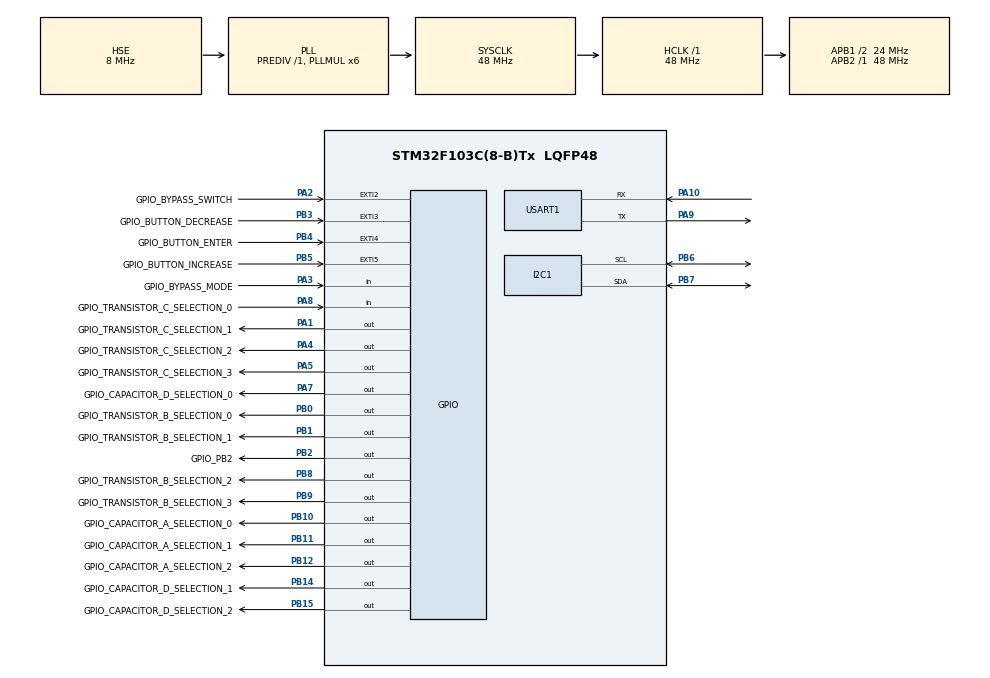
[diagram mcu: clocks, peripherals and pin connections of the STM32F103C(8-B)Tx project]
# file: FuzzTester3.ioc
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I2C1.I2C_Mode=I2C_Standard
Mcu.Family=STM32F1
Mcu.Name=STM32F103C(8-B)Tx
Mcu.Package=LQFP48
NVIC.EXTI2_IRQn=true\:0\:0\:false\:false\:true\:true\:true
NVIC.EXTI3_IRQn=true\:0\:0\:false\:false\:true\:true\:true
NVIC.EXTI4_IRQn=true\:0\:0\:false\:false\:true\:true\:true
NVIC.EXTI9_5_IRQn=true\:0\:0\:false\:false\:true\:true\:true
NVIC.PriorityGroup=NVIC_PRIORITYGROUP_4
PA1.GPIO_Label=GPIO_TRANSISTOR_C_SELECTION_1
PA1.Signal=GPIO_Output
PA10.Mode=Asynchronous
PA10.Signal=USART1_RX
PA13.Mode=Serial_Wire
PA13.Signal=SYS_JTMS-SWDIO
PA14.Mode=Serial_Wire
PA14.Signal=SYS_JTCK-SWCLK
PA2.GPIO_Label=GPIO_BYPASS_SWITCH
PA2.GPIO_PuPd=GPIO_PULLDOWN
PA2.Signal=GPXTI2
PA3.GPIO_Label=GPIO_BYPASS_MODE
PA3.Signal=GPIO_Input
PA4.GPIO_Label=GPIO_TRANSISTOR_C_SELECTION_2
PA4.Signal=GPIO_Output
PA5.GPIO_Label=GPIO_TRANSISTOR_C_SELECTION_3
PA5.Signal=GPIO_Output
PA7.GPIO_Label=GPIO_CAPACITOR_D_SELECTION_0
PA7.Signal=GPIO_Output
PA8.GPIO_Label=GPIO_TRANSISTOR_C_SELECTION_0
PA8.Signal=GPIO_Input
PA9.Mode=Asynchronous
PA9.Signal=USART1_TX
PB0.GPIO_Label=GPIO_TRANSISTOR_B_SELECTION_0
PB0.Signal=GPIO_Output
PB1.GPIO_Label=GPIO_TRANSISTOR_B_SELECTION_1
PB1.Signal=GPIO_Output
PB10.GPIO_Label=GPIO_CAPACITOR_A_SELECTION_0
PB10.Signal=GPIO_Output
PB11.GPIO_Label=GPIO_CAPACITOR_A_SELECTION_1
PB11.Signal=GPIO_Output
PB12.GPIO_Label=GPIO_CAPACITOR_A_SELECTION_2
PB12.Signal=GPIO_Output
PB14.GPIO_Label=GPIO_CAPACITOR_D_SELECTION_1
PB14.Signal=GPIO_Output
PB15.GPIO_Label=GPIO_CAPACITOR_D_SELECTION_2
PB15.Signal=GPIO_Output
PB2.GPIO_Label=GPIO_PB2
PB2.GPIO_PuPd=GPIO_NOPULL
PB2.Signal=GPIO_Output
PB3.GPIO_Label=GPIO_BUTTON_DECREASE
PB3.GPIO_PuPd=GPIO_PULLDOWN
PB3.Signal=GPXTI3
PB4.GPIO_Label=GPIO_BUTTON_ENTER
PB4.GPIO_PuPd=GPIO_PULLDOWN
PB4.Signal=GPXTI4
PB5.GPIO_Label=GPIO_BUTTON_INCREASE
PB5.GPIO_PuPd=GPIO_PULLDOWN
PB5.Signal=GPXTI5
PB6.Mode=I2C
PB6.Signal=I2C1_SCL
PB7.Mode=I2C
PB7.Signal=I2C1_SDA
PB8.GPIO_Label=GPIO_TRANSISTOR_B_SELECTION_2
PB8.Signal=GPIO_Output
PB9.GPIO_Label=GPIO_TRANSISTOR_B_SELECTION_3
PB9.Signal=GPIO_Output
PD0-OSC_IN.Mode=HSE-External-Oscillator
PD0-OSC_IN.Signal=RCC_OSC_IN
PD1-OSC_OUT.Mode=HSE-External-Oscillator
PD1-OSC_OUT.Signal=RCC_OSC_OUT
ProjectManager.HeapSize=0x200
ProjectManager.StackSize=0x400
ProjectManager.TargetToolchain=STM32CubeIDE
RCC.ADCPresc=RCC_ADCPCLK2_DIV6
RCC.AHBFreq_Value=48000000
RCC.APB1CLKDivider=RCC_HCLK_DIV2
RCC.APB1Freq_Value=24000000
RCC.APB1TimFreq_Value=48000000
RCC.APB2Freq_Value=48000000
RCC.APB2TimFreq_Value=48000000
RCC.HCLKFreq_Value=48000000
RCC.PLLMUL=RCC_PLL_MUL6
RCC.PLLSourceVirtual=RCC_PLLSOURCE_HSE
RCC.SYSCLKFreq_VALUE=48000000
RCC.SYSCLKSource=RCC_SYSCLKSOURCE_PLLCLK
RCC.USBFreq_Value=48000000
USART1.VirtualMode=VM_ASYNC
board=custom

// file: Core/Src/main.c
/* USER CODE BEGIN Header */
/**
  ******************************************************************************
  * @file           : main.c
  * @brief          : Main program body
  ******************************************************************************
  * @attention
  *
  * <h2><center>&copy; Copyright (c) 2020 STMicroelectronics.
  * All rights reserved.</center></h2>
  *
  * This software component is licensed by ST under BSD 3-Clause license,
  * the "License"; You may not use this file except in compliance with the
  * License. You may obtain a copy of the License at:
  *                        opensource.org/licenses/BSD-3-Clause
  *
  ******************************************************************************
  */
/* USER CODE END Header */

#include "main.h"

I2C_HandleTypeDef hi2c1;

UART_HandleTypeDef huart1;

void SystemClock_Config(void);
static void MX_GPIO_Init(void);
static void MX_I2C1_Init(void);
static void MX_USART1_UART_Init(void);
/* USER CODE BEGIN PFP */

void MyInit();
int  MyMain();

/* USER CODE END PFP */

int main(void)
{

  /* MCU Configuration--------------------------------------------------------*/

  /* Reset of all peripherals, Initializes the Flash interface and the Systick. */
  HAL_Init();

  /* Configure the system clock */
  SystemClock_Config();

  /* Initialize all configured peripherals */
  MX_GPIO_Init();
  MX_I2C1_Init();
  MX_USART1_UART_Init();

  /* Infinite loop */
  /* USER CODE BEGIN WHILE */
  MyInit();
  while (1)
  {
     MyMain();

    /* USER CODE END WHILE */

  }
}

void SystemClock_Config(void)
{
  RCC_OscInitTypeDef RCC_OscInitStruct = {0};
  RCC_ClkInitTypeDef RCC_ClkInitStruct = {0};

  /** Initializes the CPU, AHB and APB busses clocks
  */
  RCC_OscInitStruct.OscillatorType = RCC_OSCILLATORTYPE_HSE;
  RCC_OscInitStruct.HSEState = RCC_HSE_ON;
  RCC_OscInitStruct.HSEPredivValue = RCC_HSE_PREDIV_DIV1;
  RCC_OscInitStruct.HSIState = RCC_HSI_ON;
  RCC_OscInitStruct.PLL.PLLState = RCC_PLL_ON;
  RCC_OscInitStruct.PLL.PLLSource = RCC_PLLSOURCE_HSE;
  RCC_OscInitStruct.PLL.PLLMUL = RCC_PLL_MUL6;
  if (HAL_RCC_OscConfig(&RCC_OscInitStruct) != HAL_OK)
  {
    Error_Handler();
  }
  /** Initializes the CPU, AHB and APB busses clocks
  */
  RCC_ClkInitStruct.ClockType = RCC_CLOCKTYPE_HCLK|RCC_CLOCKTYPE_SYSCLK
                              |RCC_CLOCKTYPE_PCLK1|RCC_CLOCKTYPE_PCLK2;
  RCC_ClkInitStruct.SYSCLKSource = RCC_SYSCLKSOURCE_PLLCLK;
  RCC_ClkInitStruct.AHBCLKDivider = RCC_SYSCLK_DIV1;
  RCC_ClkInitStruct.APB1CLKDivider = RCC_HCLK_DIV2;
  RCC_ClkInitStruct.APB2CLKDivider = RCC_HCLK_DIV1;

  if (HAL_RCC_ClockConfig(&RCC_ClkInitStruct, FLASH_LATENCY_1) != HAL_OK)
  {
    Error_Handler();
  }
}

static void MX_I2C1_Init(void)
{

  hi2c1.Instance = I2C1;
  hi2c1.Init.ClockSpeed = 100000;
  hi2c1.Init.DutyCycle = I2C_DUTYCYCLE_2;
  hi2c1.Init.OwnAddress1 = 0;
  hi2c1.Init.AddressingMode = I2C_ADDRESSINGMODE_7BIT;
  hi2c1.Init.DualAddressMode = I2C_DUALADDRESS_DISABLE;
  hi2c1.Init.OwnAddress2 = 0;
  hi2c1.Init.GeneralCallMode = I2C_GENERALCALL_DISABLE;
  hi2c1.Init.NoStretchMode = I2C_NOSTRETCH_DISABLE;
  if (HAL_I2C_Init(&hi2c1) != HAL_OK)
  {
    Error_Handler();
  }

}

static void MX_USART1_UART_Init(void)
{

  huart1.Instance = USART1;
  huart1.Init.BaudRate = 115200;
  huart1.Init.WordLength = UART_WORDLENGTH_8B;
  huart1.Init.StopBits = UART_STOPBITS_1;
  huart1.Init.Parity = UART_PARITY_NONE;
  huart1.Init.Mode = UART_MODE_TX_RX;
  huart1.Init.HwFlowCtl = UART_HWCONTROL_NONE;
  huart1.Init.OverSampling = UART_OVERSAMPLING_16;
  if (HAL_UART_Init(&huart1) != HAL_OK)
  {
    Error_Handler();
  }

}

static void MX_GPIO_Init(void)
{
  GPIO_InitTypeDef GPIO_InitStruct = {0};

  /* GPIO Ports Clock Enable */
  __HAL_RCC_GPIOD_CLK_ENABLE();
  __HAL_RCC_GPIOA_CLK_ENABLE();
  __HAL_RCC_GPIOB_CLK_ENABLE();

  /*Configure GPIO pin Output Level */
  HAL_GPIO_WritePin(GPIOA, GPIO_TRANSISTOR_C_SELECTION_1_Pin|GPIO_TRANSISTOR_C_SELECTION_2_Pin|GPIO_TRANSISTOR_C_SELECTION_3_Pin|GPIO_CAPACITOR_D_SELECTION_0_Pin, GPIO_PIN_RESET);

  /*Configure GPIO pin Output Level */
  HAL_GPIO_WritePin(GPIOB, GPIO_TRANSISTOR_B_SELECTION_0_Pin|GPIO_TRANSISTOR_B_SELECTION_1_Pin|GPIO_PB2_Pin|GPIO_CAPACITOR_A_SELECTION_0_Pin
                          |GPIO_CAPACITOR_A_SELECTION_1_Pin|GPIO_CAPACITOR_A_SELECTION_2_Pin|GPIO_CAPACITOR_D_SELECTION_1_Pin|GPIO_CAPACITOR_D_SELECTION_2_Pin
                          |GPIO_TRANSISTOR_B_SELECTION_2_Pin|GPIO_TRANSISTOR_B_SELECTION_3_Pin, GPIO_PIN_RESET);

  /*Configure GPIO pins : GPIO_TRANSISTOR_C_SELECTION_1_Pin GPIO_TRANSISTOR_C_SELECTION_2_Pin GPIO_TRANSISTOR_C_SELECTION_3_Pin GPIO_CAPACITOR_D_SELECTION_0_Pin */
  GPIO_InitStruct.Pin = GPIO_TRANSISTOR_C_SELECTION_1_Pin|GPIO_TRANSISTOR_C_SELECTION_2_Pin|GPIO_TRANSISTOR_C_SELECTION_3_Pin|GPIO_CAPACITOR_D_SELECTION_0_Pin;
  GPIO_InitStruct.Mode = GPIO_MODE_OUTPUT_PP;
  GPIO_InitStruct.Pull = GPIO_NOPULL;
  GPIO_InitStruct.Speed = GPIO_SPEED_FREQ_LOW;
  HAL_GPIO_Init(GPIOA, &GPIO_InitStruct);

  /*Configure GPIO pin : GPIO_BYPASS_SWITCH_Pin */
  GPIO_InitStruct.Pin = GPIO_BYPASS_SWITCH_Pin;
  GPIO_InitStruct.Mode = GPIO_MODE_IT_RISING;
  GPIO_InitStruct.Pull = GPIO_PULLDOWN;
  HAL_GPIO_Init(GPIO_BYPASS_SWITCH_GPIO_Port, &GPIO_InitStruct);

  /*Configure GPIO pins : GPIO_BYPASS_MODE_Pin GPIO_TRANSISTOR_C_SELECTION_0_Pin */
  GPIO_InitStruct.Pin = GPIO_BYPASS_MODE_Pin|GPIO_TRANSISTOR_C_SELECTION_0_Pin;
  GPIO_InitStruct.Mode = GPIO_MODE_INPUT;
  GPIO_InitStruct.Pull = GPIO_NOPULL;
  HAL_GPIO_Init(GPIOA, &GPIO_InitStruct);

  /*Configure GPIO pins : GPIO_TRANSISTOR_B_SELECTION_0_Pin GPIO_TRANSISTOR_B_SELECTION_1_Pin GPIO_PB2_Pin GPIO_CAPACITOR_A_SELECTION_0_Pin
                           GPIO_CAPACITOR_A_SELECTION_1_Pin GPIO_CAPACITOR_A_SELECTION_2_Pin GPIO_CAPACITOR_D_SELECTION_1_Pin GPIO_CAPACITOR_D_SELECTION_2_Pin
                           GPIO_TRANSISTOR_B_SELECTION_2_Pin GPIO_TRANSISTOR_B_SELECTION_3_Pin */
  GPIO_InitStruct.Pin = GPIO_TRANSISTOR_B_SELECTION_0_Pin|GPIO_TRANSISTOR_B_SELECTION_1_Pin|GPIO_PB2_Pin|GPIO_CAPACITOR_A_SELECTION_0_Pin
                          |GPIO_CAPACITOR_A_SELECTION_1_Pin|GPIO_CAPACITOR_A_SELECTION_2_Pin|GPIO_CAPACITOR_D_SELECTION_1_Pin|GPIO_CAPACITOR_D_SELECTION_2_Pin
                          |GPIO_TRANSISTOR_B_SELECTION_2_Pin|GPIO_TRANSISTOR_B_SELECTION_3_Pin;
  GPIO_InitStruct.Mode = GPIO_MODE_OUTPUT_PP;
  GPIO_InitStruct.Pull = GPIO_NOPULL;
  GPIO_InitStruct.Speed = GPIO_SPEED_FREQ_LOW;
  HAL_GPIO_Init(GPIOB, &GPIO_InitStruct);

  /*Configure GPIO pins : GPIO_BUTTON_DECREASE_Pin GPIO_BUTTON_ENTER_Pin GPIO_BUTTON_INCREASE_Pin */
  GPIO_InitStruct.Pin = GPIO_BUTTON_DECREASE_Pin|GPIO_BUTTON_ENTER_Pin|GPIO_BUTTON_INCREASE_Pin;
  GPIO_InitStruct.Mode = GPIO_MODE_IT_RISING;
  GPIO_InitStruct.Pull = GPIO_PULLDOWN;
  HAL_GPIO_Init(GPIOB, &GPIO_InitStruct);

  /* EXTI interrupt init*/
  HAL_NVIC_SetPriority(EXTI2_IRQn, 0, 0);
  HAL_NVIC_EnableIRQ(EXTI2_IRQn);

  HAL_NVIC_SetPriority(EXTI3_IRQn, 0, 0);
  HAL_NVIC_EnableIRQ(EXTI3_IRQn);

  HAL_NVIC_SetPriority(EXTI4_IRQn, 0, 0);
  HAL_NVIC_EnableIRQ(EXTI4_IRQn);

  HAL_NVIC_SetPriority(EXTI9_5_IRQn, 0, 0);
  HAL_NVIC_EnableIRQ(EXTI9_5_IRQn);

}

void Error_Handler(void)
{
}

#ifdef  USE_FULL_ASSERT
/**
  * @brief  Reports the name of the source file and the source line number
  *         where the assert_param error has occurred.
  * @param  file: pointer to the source file name
  * @param  line: assert_param error line source number
  * @retval None
  */
void assert_failed(uint8_t *file, uint32_t line)
{
  /* USER CODE BEGIN 6 */
  /* User can add his own implementation to report the file name and line number,
     text: printf("Wrong parameters value: file %s on line %d\r\n", file, line) */
  /* USER CODE END 6 */
}
#endif /* USE_FULL_ASSERT */

/************************ (C) COPYRIGHT STMicroelectronics *****END OF FILE****/
